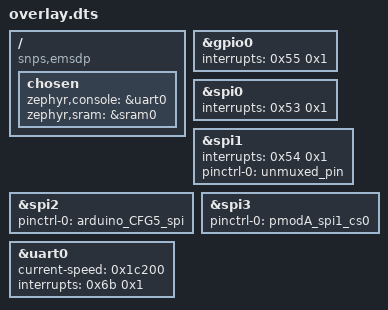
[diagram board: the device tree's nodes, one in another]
/ {
	compatible = "snps,emsdp", "snps,emsdp";
	chosen {
		zephyr,console = &uart0;
		zephyr,sram = &sram0;
	};
};
&gpio0{
	interrupts = < 0x55 0x1 >;
};
&spi0{
	interrupts = < 0x53 0x1 >;
};
&spi1{
	interrupts = < 0x54 0x1 >;
	pinctrl-0 = < &unmuxed_pin >;
	pinctrl-names = "default";
};
&spi2{
	pinctrl-0 = < &arduino_CFG5_spi >;
	pinctrl-names = "default";
};
&spi3{
	pinctrl-0 = < &pmodA_spi1_cs0 >;
	pinctrl-names = "default";
};
&uart0{
	status = "okay";
	current-speed = < 0x1c200 >;
	interrupts = < 0x6b 0x1 >;
};
